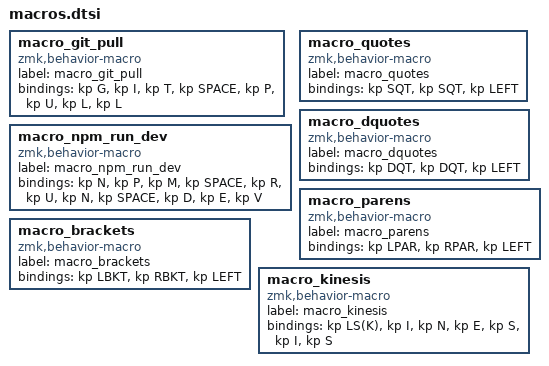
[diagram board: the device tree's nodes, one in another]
macro_git_pull: macro_git_pull{
compatible = "zmk,behavior-macro";
label = "macro_git_pull";
#binding-cells = <0>;
bindings = <&kp G>, <&kp I>, <&kp T>, <&kp SPACE>, <&kp P>, <&kp U>, <&kp L>, <&kp L>;
};
macro_npm_run_dev: macro_npm_run_dev{
compatible = "zmk,behavior-macro";
label = "macro_npm_run_dev";
#binding-cells = <0>;
bindings = <&kp N>, <&kp P>, <&kp M>, <&kp SPACE>, <&kp R>, <&kp U>, <&kp N>, <&kp SPACE>, <&kp D>, <&kp E>, <&kp V>;
};
macro_quotes: macro_quotes{
compatible = "zmk,behavior-macro";
label = "macro_quotes";
#binding-cells = <0>;
bindings = <&kp SQT>, <&kp SQT>, <&kp LEFT>;
};
macro_dquotes: macro_dquotes{
compatible = "zmk,behavior-macro";
label = "macro_dquotes";
#binding-cells = <0>;
bindings = <&kp DQT>, <&kp DQT>, <&kp LEFT>;
};
macro_parens: macro_parens{
compatible = "zmk,behavior-macro";
label = "macro_parens";
#binding-cells = <0>;
bindings = <&kp LPAR>, <&kp RPAR>, <&kp LEFT>;
};
macro_brackets: macro_brackets{
compatible = "zmk,behavior-macro";
label = "macro_brackets";
#binding-cells = <0>;
bindings = <&kp LBKT>, <&kp RBKT>, <&kp LEFT>;
};
macro_kinesis: macro_kinesis{
compatible = "zmk,behavior-macro";
label = "macro_kinesis";
#binding-cells = <0>;
bindings = <&kp LS(K)>, <&kp I>, <&kp N>, <&kp E>, <&kp S>, <&kp I>, <&kp S>;
};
